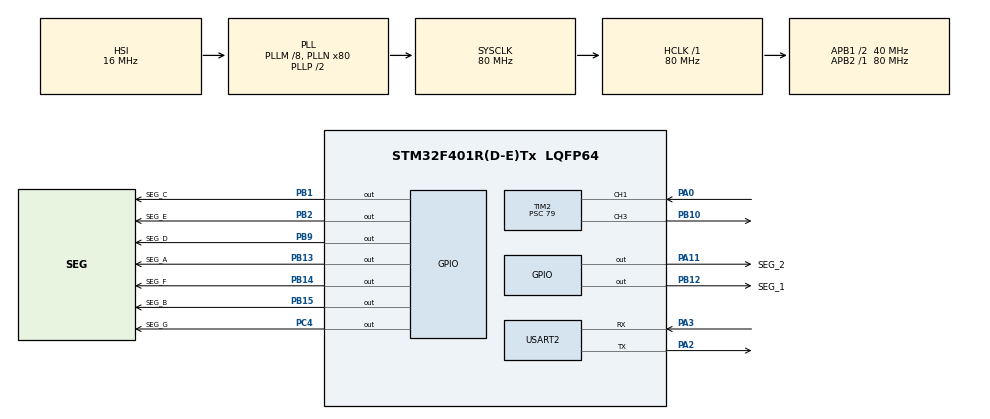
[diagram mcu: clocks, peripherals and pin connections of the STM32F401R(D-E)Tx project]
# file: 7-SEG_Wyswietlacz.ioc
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Mcu.Family=STM32F4
Mcu.Name=STM32F401R(D-E)Tx
Mcu.Package=LQFP64
NVIC.PriorityGroup=NVIC_PRIORITYGROUP_4
NVIC.TIM2_IRQn=true\:10\:0\:true\:false\:true\:true\:true
PA0-WKUP.Signal=S_TIM2_CH1_ETR
PA11.GPIO_Label=SEG_2
PA11.GPIO_ModeDefaultOutputPP=GPIO_MODE_OUTPUT_PP
PA11.GPIO_PuPd=GPIO_NOPULL
PA11.PinState=GPIO_PIN_SET
PA11.Signal=GPIO_Output
PA13.Mode=Serial_Wire
PA13.Signal=SYS_JTMS-SWDIO
PA14.Mode=Serial_Wire
PA14.Signal=SYS_JTCK-SWCLK
PA2.Mode=Asynchronous
PA2.Signal=USART2_TX
PA3.Mode=Asynchronous
PA3.Signal=USART2_RX
PB1.GPIO_Label=SEG_C
PB1.PinState=GPIO_PIN_SET
PB1.Signal=GPIO_Output
PB10.Signal=S_TIM2_CH3
PB12.GPIO_Label=SEG_1
PB12.GPIO_ModeDefaultOutputPP=GPIO_MODE_OUTPUT_PP
PB12.GPIO_PuPd=GPIO_NOPULL
PB12.PinState=GPIO_PIN_SET
PB12.Signal=GPIO_Output
PB13.GPIO_Label=SEG_A
PB13.PinState=GPIO_PIN_SET
PB13.Signal=GPIO_Output
PB14.GPIO_Label=SEG_F
PB14.PinState=GPIO_PIN_SET
PB14.Signal=GPIO_Output
PB15.GPIO_Label=SEG_B
PB15.PinState=GPIO_PIN_SET
PB15.Signal=GPIO_Output
PB2.GPIO_Label=SEG_E
PB2.PinState=GPIO_PIN_SET
PB2.Signal=GPIO_Output
PB9.GPIO_Label=SEG_D
PB9.PinState=GPIO_PIN_SET
PB9.Signal=GPIO_Output
PC4.GPIO_Label=SEG_G
PC4.PinState=GPIO_PIN_SET
PC4.Signal=GPIO_Output
ProjectManager.HeapSize=0x200
ProjectManager.StackSize=0x400
ProjectManager.TargetToolchain=STM32CubeIDE
RCC.48MHZClocksFreq_Value=40000000
RCC.AHBFreq_Value=80000000
RCC.APB1CLKDivider=RCC_HCLK_DIV2
RCC.APB1Freq_Value=40000000
RCC.APB1TimFreq_Value=80000000
RCC.APB2Freq_Value=80000000
RCC.APB2TimFreq_Value=80000000
RCC.CortexFreq_Value=80000000
RCC.HCLKFreq_Value=80000000
RCC.HSE_VALUE=25000000
RCC.HSI_VALUE=16000000
RCC.LSE_VALUE=32768
RCC.PLLM=8
RCC.PLLN=80
RCC.SYSCLKFreq_VALUE=80000000
RCC.SYSCLKSource=RCC_SYSCLKSOURCE_PLLCLK
RCC.VCOOutputFreq_Value=160000000
SH.S_TIM2_CH1_ETR.0=TIM2_CH1,Input_Capture1_from_TI1
SH.S_TIM2_CH3.0=TIM2_CH3,PWM Generation3 CH3
TIM2.Channel-Input_Capture1_from_TI1=TIM_CHANNEL_1
TIM2.Channel-Input_Capture2_from_TI1_63=TIM_CHANNEL_2
TIM2.Channel-PWM\ Generation3\ CH3=TIM_CHANNEL_3
TIM2.ICPolarity_CH1=TIM_INPUTCHANNELPOLARITY_RISING
TIM2.ICPolarity_CH2=TIM_INPUTCHANNELPOLARITY_FALLING
TIM2.Period=999999
TIM2.Prescaler=79
TIM2.Pulse-PWM\ Generation3\ CH3=10
USART2.VirtualMode=VM_ASYNC
VP_TIM2_VS_ClockSourceINT.Mode=Internal
VP_TIM2_VS_indirect_ch1.Mode=Input_Capture2_from_TI1_63
board=custom

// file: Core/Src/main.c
/* USER CODE BEGIN Header */
/**
  ******************************************************************************
  * @file           : main.c
  * @brief          : Main program body
  ******************************************************************************
  * @attention
  *
  * Copyright (c) 2023 STMicroelectronics.
  * All rights reserved.
  *
  * This software is licensed under terms that can be found in the LICENSE file
  * in the root directory of this software component.
  * If no LICENSE file comes with this software, it is provided AS-IS.
  *
  ******************************************************************************
  */
/* USER CODE END Header */
#include "main.h"
#include "tim.h"
#include "usart.h"
#include "gpio.h"

/* USER CODE BEGIN Includes */
#include <stdio.h>
#include "seg7.h"
/* USER CODE END Includes */

void SystemClock_Config(void);

/* USER CODE BEGIN 0 */
int __io_putchar(int ch)
{
  if (ch == '\n') {
    __io_putchar('\r');
  }

  HAL_UART_Transmit(&huart2, (uint8_t*)&ch, 1, HAL_MAX_DELAY);

  return 1;
}

/* USER CODE END 0 */

int main(void)
{

  /* MCU Configuration--------------------------------------------------------*/

  /* Reset of all peripherals, Initializes the Flash interface and the Systick. */
  HAL_Init();

  /* Configure the system clock */
  SystemClock_Config();

  /* Initialize all configured peripherals */
  MX_GPIO_Init();
  MX_TIM2_Init();
  MX_USART2_UART_Init();

  /* Infinite loop */
  /* USER CODE BEGIN WHILE */

int value=0;
  while (1)
  {

	seg7_show(value);
	 value++;
	seg7_update();
	HAL_Delay(500);
	 // 	seg7_update();
	// 	HAL_GPIO_WritePin(SEG_1_GPIO_Port, SEG_1_Pin, GPIO_PIN_RESET);
	//  	HAL_GPIO_WritePin(SEG_2_GPIO_Port, SEG_2_Pin, GPIO_PIN_SET);
	//for (int i = 0; i < 10; i++) {
	//  	  seg7_show_digit(i);
	//    HAL_Delay(500);
	//   }
    /* USER CODE END WHILE */

  }
}

void SystemClock_Config(void)
{
  RCC_OscInitTypeDef RCC_OscInitStruct = {0};
  RCC_ClkInitTypeDef RCC_ClkInitStruct = {0};

  /** Configure the main internal regulator output voltage
  */
  __HAL_RCC_PWR_CLK_ENABLE();
  __HAL_PWR_VOLTAGESCALING_CONFIG(PWR_REGULATOR_VOLTAGE_SCALE2);
  /** Initializes the RCC Oscillators according to the specified parameters
  * in the RCC_OscInitTypeDef structure.
  */
  RCC_OscInitStruct.OscillatorType = RCC_OSCILLATORTYPE_HSI;
  RCC_OscInitStruct.HSIState = RCC_HSI_ON;
  RCC_OscInitStruct.HSICalibrationValue = RCC_HSICALIBRATION_DEFAULT;
  RCC_OscInitStruct.PLL.PLLState = RCC_PLL_ON;
  RCC_OscInitStruct.PLL.PLLSource = RCC_PLLSOURCE_HSI;
  RCC_OscInitStruct.PLL.PLLM = 8;
  RCC_OscInitStruct.PLL.PLLN = 80;
  RCC_OscInitStruct.PLL.PLLP = RCC_PLLP_DIV2;
  RCC_OscInitStruct.PLL.PLLQ = 4;
  if (HAL_RCC_OscConfig(&RCC_OscInitStruct) != HAL_OK)
  {
    Error_Handler();
  }
  /** Initializes the CPU, AHB and APB buses clocks
  */
  RCC_ClkInitStruct.ClockType = RCC_CLOCKTYPE_HCLK|RCC_CLOCKTYPE_SYSCLK
                              |RCC_CLOCKTYPE_PCLK1|RCC_CLOCKTYPE_PCLK2;
  RCC_ClkInitStruct.SYSCLKSource = RCC_SYSCLKSOURCE_PLLCLK;
  RCC_ClkInitStruct.AHBCLKDivider = RCC_SYSCLK_DIV1;
  RCC_ClkInitStruct.APB1CLKDivider = RCC_HCLK_DIV2;
  RCC_ClkInitStruct.APB2CLKDivider = RCC_HCLK_DIV1;

  if (HAL_RCC_ClockConfig(&RCC_ClkInitStruct, FLASH_LATENCY_2) != HAL_OK)
  {
    Error_Handler();
  }
}

void Error_Handler(void)
{
  __disable_irq();
  while (1)
  {
  }
}
